VERSION ""

NS_ :

BS_:

BU_: XXX

BO_ 85 CID_OBBIEO: 8 XXX
 SG_ sig_ztylyv : 40|1@1+ (1,0) [0|1] "" XXX
 SG_ sig_mnrkns : 56|8@1+ (1,0) [0|255] "" XXX

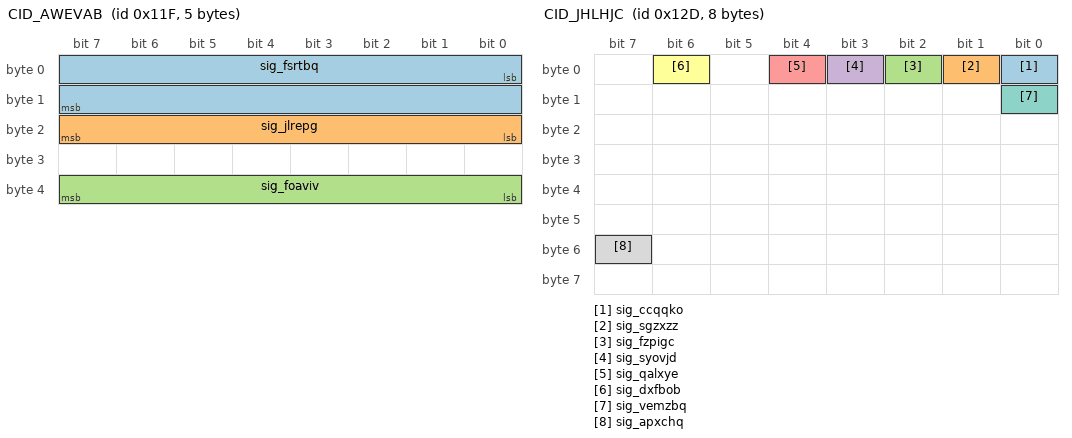
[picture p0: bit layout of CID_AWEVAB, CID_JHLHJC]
BO_ 287 CID_AWEVAB: 5 XXX
 SG_ sig_fsrtbq : 0|16@1- (0.1,0) [-450|450] "" XXX
 SG_ sig_jlrepg : 16|8@1+ (4,0) [0|1020] "" XXX
 SG_ sig_foaviv : 32|8@1+ (1,0) [0|255] "" XXX

BO_ 289 CID_IADQPU: 8 XXX
 SG_ sig_tpgtbw : 0|12@1+ (1,0) [0|255] "" XXX

BO_ 301 CID_JHLHJC: 8 XXX
 SG_ sig_ccqqko : 0|1@0+ (1,0) [0|1] "" XXX
 SG_ sig_sgzxzz : 1|1@0+ (1,0) [0|1] "" XXX
 SG_ sig_fzpigc : 2|1@0+ (1,0) [0|1] "" XXX
 SG_ sig_syovjd : 3|1@0+ (1,0) [0|1] "" XXX
 SG_ sig_qalxye : 4|1@0+ (1,0) [0|1] "" XXX
 SG_ sig_dxfbob : 6|1@0+ (1,0) [0|1] "" XXX
 SG_ sig_vemzbq : 8|1@0+ (1,0) [0|1] "" XXX
 SG_ sig_apxchq : 55|1@0+ (1,0) [0|1] "" XXX

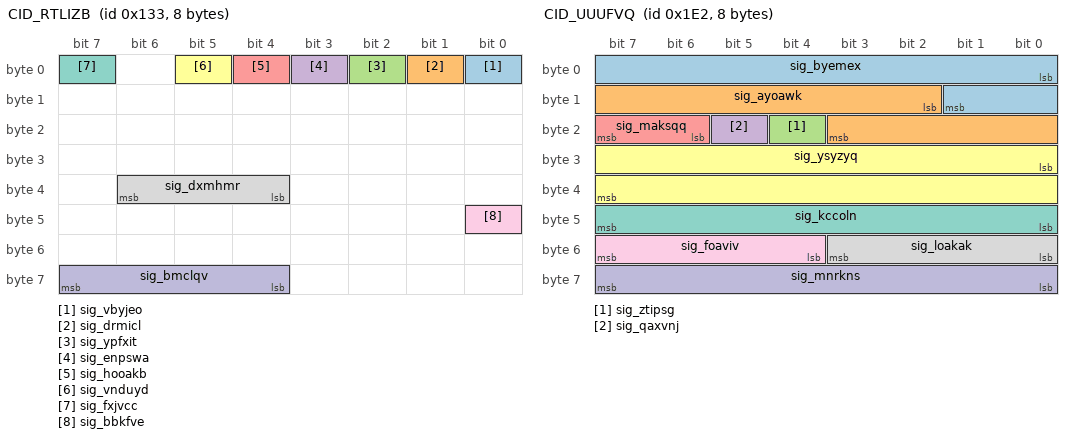
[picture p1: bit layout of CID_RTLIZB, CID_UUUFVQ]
BO_ 307 CID_RTLIZB: 8 XXX
 SG_ sig_vbyjeo : 0|1@0+ (1,0) [0|1] "" XXX
 SG_ sig_drmicl : 1|1@1+ (1,0) [0|1] "" XXX
 SG_ sig_ypfxit : 2|1@1+ (1,0) [0|1] "" XXX
 SG_ sig_enpswa : 3|1@1+ (1,0) [0|1] "" XXX
 SG_ sig_hooakb : 4|1@0+ (1,0) [0|1] "" XXX
 SG_ sig_vnduyd : 5|1@0+ (1,0) [0|1] "" XXX
 SG_ sig_fxjvcc : 7|1@0+ (1,0) [0|1] "" XXX
 SG_ sig_dxmhmr : 36|3@1+ (1,0) [0|7] "" XXX
 SG_ sig_bbkfve : 40|1@0+ (1,0) [0|1] "" XXX
 SG_ sig_bmclqv : 63|4@0+ (1,0) [0|15] "" XXX

BO_ 482 CID_UUUFVQ: 8 XXX
 SG_ sig_byemex : 0|10@1- (0.01,0) [0|5] "" XXX
 SG_ sig_ayoawk : 10|10@1- (0.01,0) [-5|0] "" XXX
 SG_ sig_ztipsg : 20|1@0+ (1,0) [0|1] "" XXX
 SG_ sig_qaxvnj : 21|1@0+ (1,0) [0|1] "" XXX
 SG_ sig_maksqq : 22|2@1+ (1,0) [0|1] "" XXX
 SG_ sig_ysyzyq : 24|16@1- (0.1,0) [-780|779.9] "" XXX
 SG_ sig_kccoln : 47|8@0+ (1,0) [0|255] "" XXX
 SG_ sig_loakak : 48|4@1+ (1,0) [0|15] "" XXX
 SG_ sig_foaviv : 52|4@1+ (1,0) [0|15] "" XXX
 SG_ sig_mnrkns : 56|8@1+ (1,0) [0|255] "" XXX

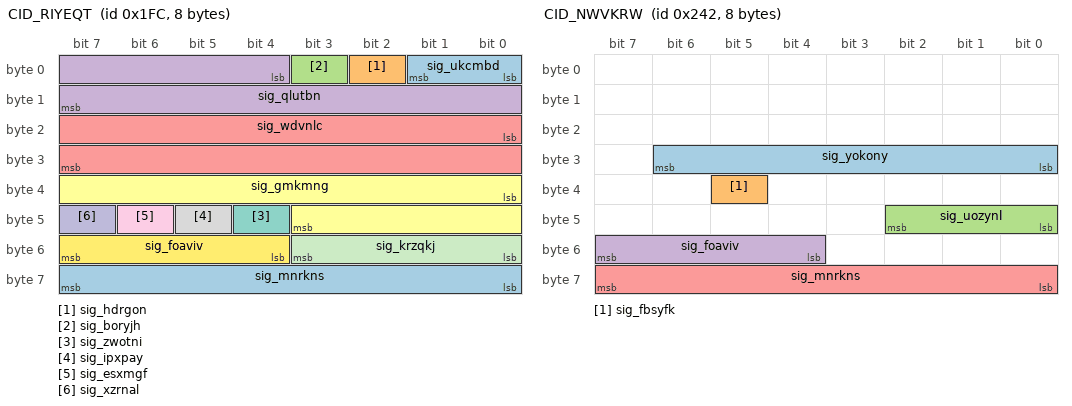
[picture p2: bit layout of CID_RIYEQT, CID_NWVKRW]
BO_ 508 CID_RIYEQT: 8 XXX
 SG_ sig_ukcmbd : 0|2@1+ (1,0) [0|1] "" XXX
 SG_ sig_hdrgon : 2|1@1+ (1,0) [0|1] "" XXX
 SG_ sig_boryjh : 3|1@0+ (1,0) [0|1] "" XXX
 SG_ sig_qlutbn : 4|12@1- (1,0) [-2048|2047] "" XXX
 SG_ sig_wdvnlc : 16|16@1- (0.1,0) [-780|779.9] "Deg" XXX
 SG_ sig_gmkmng : 32|12@1- (0.01,0) [0|63] "" XXX
 SG_ sig_zwotni : 44|1@0+ (1,0) [0|1] "" XXX
 SG_ sig_ipxpay : 45|1@1+ (1,0) [0|255] "" XXX
 SG_ sig_esxmgf : 46|1@1+ (1,0) [0|1] "" XXX
 SG_ sig_xzrnal : 47|1@0+ (1,0) [0|3] "" XXX
 SG_ sig_krzqkj : 48|4@1+ (1,0) [0|15] "" XXX
 SG_ sig_foaviv : 52|4@1+ (1,0) [0|15] "" XXX
 SG_ sig_mnrkns : 56|8@1+ (1,0) [0|255] "" XXX

BO_ 578 CID_NWVKRW: 8 XXX
 SG_ sig_yokony : 30|7@0+ (1,0) [0|127] "" XXX
 SG_ sig_fbsyfk : 37|1@0+ (1,0) [0|1] "" XXX
 SG_ sig_uozynl : 40|3@1+ (1,0) [0|7] "" XXX
 SG_ sig_foaviv : 55|4@0+ (1,0) [0|15] "" XXX
 SG_ sig_mnrkns : 56|8@1+ (1,0) [0|255] "" XXX

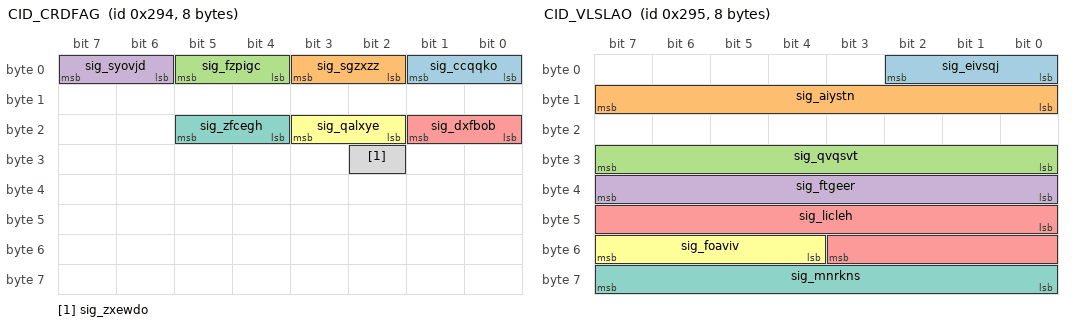
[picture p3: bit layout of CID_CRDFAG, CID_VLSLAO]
BO_ 660 CID_CRDFAG: 8 XXX
 SG_ sig_ccqqko : 1|2@0+ (1,0) [0|3] "" XXX
 SG_ sig_sgzxzz : 3|2@0+ (1,0) [0|3] "" XXX
 SG_ sig_fzpigc : 5|2@0+ (1,0) [0|3] "" XXX
 SG_ sig_syovjd : 7|2@0+ (1,0) [0|3] "" XXX
 SG_ sig_dxfbob : 17|2@0+ (1,0) [0|3] "" XXX
 SG_ sig_qalxye : 19|2@0+ (1,0) [0|3] "" XXX
 SG_ sig_zfcegh : 21|2@0+ (1,0) [0|3] "" XXX
 SG_ sig_zxewdo : 26|1@0+ (1,0) [0|1] "" XXX

BO_ 661 CID_VLSLAO: 8 XXX
 SG_ sig_eivsqj : 2|3@0+ (1,0) [0|7] "" XXX
 SG_ sig_aiystn : 15|8@0+ (1,0) [0|255] "" XXX
 SG_ sig_qvqsvt : 31|8@0+ (1,0) [0|255] "" XXX
 SG_ sig_ftgeer : 32|8@1+ (1,0) [0|255] "" XXX
 SG_ sig_licleh : 40|12@1+ (1,0) [0|255] "" XXX
 SG_ sig_foaviv : 52|4@1+ (1,0) [0|15] "" XXX
 SG_ sig_mnrkns : 63|8@0+ (1,0) [0|255] "" XXX

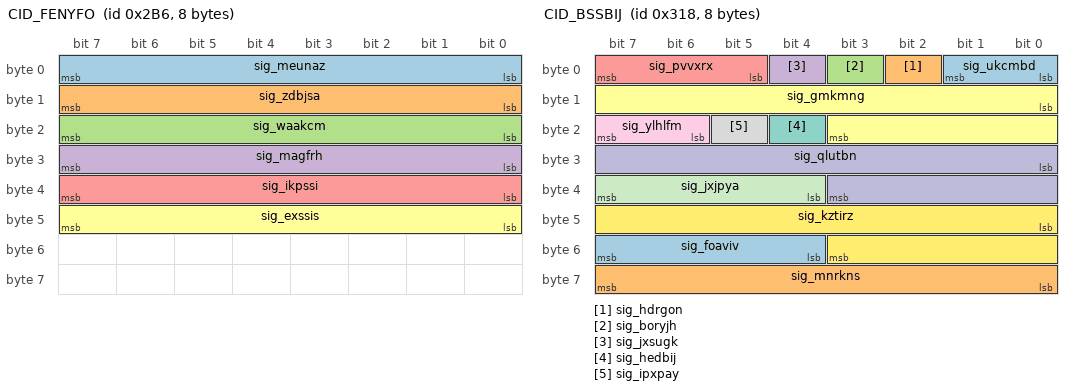
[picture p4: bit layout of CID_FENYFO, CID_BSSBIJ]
BO_ 694 CID_FENYFO: 8 XXX
 SG_ sig_meunaz : 7|8@0+ (1,0) [0|255] "" XXX
 SG_ sig_zdbjsa : 15|8@0+ (1,0) [0|255] "" XXX
 SG_ sig_waakcm : 23|8@0+ (1,0) [0|255] "" XXX
 SG_ sig_magfrh : 31|8@0+ (1,0) [0|255] "" XXX
 SG_ sig_ikpssi : 39|8@0+ (1,0) [0|255] "" XXX
 SG_ sig_exssis : 47|8@0+ (1,0) [0|255] "" XXX

BO_ 790 CID_SJYXFS: 8 XXX
 SG_ sig_xmqwfm : 3|4@0+ (1,0) [0|1] "" XXX
 SG_ sig_wkslko : 4|2@1+ (1,0) [0|3] "" XXX
 SG_ sig_kwgcie : 6|2@1+ (1,0) [0|3] "" XXX
 SG_ sig_zuxlpg : 8|2@1+ (1,0) [0|3] "" XXX
 SG_ sig_cudveg : 10|1@1+ (1,0) [0|1] "" XXX
 SG_ sig_dhqlja : 11|4@1+ (1,0) [0|1] "" XXX
 SG_ sig_aytxbb : 15|1@0+ (1,0) [0|1] "" XXX
 SG_ sig_ysyzyq : 16|11@1- (1,0) [-1024|1023] "" XXX
 SG_ sig_ztipsg : 27|1@1+ (1,0) [0|1] "" XXX
 SG_ sig_qaxvnj : 28|1@1+ (1,0) [0|3] "" XXX
 SG_ sig_kjrufc : 29|1@0+ (1,0) [0|1] "" XXX
 SG_ sig_eovbcm : 30|1@0+ (1,0) [0|1] "" XXX
 SG_ sig_phblbt : 31|1@0+ (1,0) [0|1] "" XXX
 SG_ sig_gevymy : 32|2@1+ (1,0) [0|3] "" XXX
 SG_ sig_ntkcop : 34|2@1+ (1,0) [0|3] "" XXX
 SG_ sig_kwwqzx : 36|4@1+ (1,0) [0|3] "" XXX
 SG_ sig_ixvluv : 40|8@1+ (5,-5) [-5|1270] "" XXX
 SG_ sig_lbctgd : 49|2@0+ (1,0) [0|3] "" XXX
 SG_ sig_plknqa : 51|2@0+ (1,0) [0|3] "" XXX
 SG_ sig_foaviv : 52|4@1+ (1,0) [0|15] "" XXX
 SG_ sig_mnrkns : 56|8@1+ (1,0) [0|15] "" XXX

BO_ 792 CID_BSSBIJ: 8 XXX
 SG_ sig_ukcmbd : 0|2@1+ (1,0) [0|1] "" XXX
 SG_ sig_hdrgon : 2|1@1+ (1,0) [0|1] "" XXX
 SG_ sig_boryjh : 3|1@1+ (1,0) [0|1] "" XXX
 SG_ sig_jxsugk : 4|1@1+ (1,0) [0|1] "" XXX
 SG_ sig_pvvxrx : 5|3@1+ (1,0) [0|1] "" XXX
 SG_ sig_gmkmng : 8|12@1- (1,0) [-2048|2047] "" XXX
 SG_ sig_hedbij : 20|1@1+ (1,0) [0|1] "" XXX
 SG_ sig_ipxpay : 21|1@1+ (1,0) [0|1] "" XXX
 SG_ sig_ylhlfm : 22|2@1+ (1,0) [0|15] "" XXX
 SG_ sig_qlutbn : 24|12@1- (1,0) [-2048|2047] "" XXX
 SG_ sig_jxjpya : 36|4@1+ (1,0) [0|15] "" XXX
 SG_ sig_kztirz : 40|12@1+ (1,0) [0|4095] "" XXX
 SG_ sig_foaviv : 52|4@1+ (1,0) [0|15] "" XXX
 SG_ sig_mnrkns : 56|8@1+ (1,0) [0|255] "" XXX

BO_ 813 CID_CFWAIZ: 8 XXX
 SG_ sig_rirhkn : 0|9@1+ (0.5,0) [0|255.5] "" XXX
 SG_ sig_psxjfy : 9|1@1+ (1,0) [0|1] "" XXX
 SG_ sig_mevbcs : 10|3@1+ (1,0) [0|7] "" XXX
 SG_ sig_zgzzio : 13|3@1+ (1,0) [0|7] "" XXX
 SG_ sig_kjnywh : 16|1@1+ (1,0) [0|1] "" XXX
 SG_ sig_ogmbuf : 17|1@1+ (1,0) [0|1] "" XXX
 SG_ sig_boryjh : 18|1@1+ (1,0) [0|1] "" XXX
 SG_ sig_sevmrq : 19|3@1+ (1,0) [0|1] "" XXX
 SG_ sig_htkqln : 22|1@0+ (1,0) [0|1] "" XXX
 SG_ sig_kjbxla : 23|1@0+ (1,0) [0|1] "" XXX
 SG_ sig_zuxlpg : 24|1@1+ (1,0) [0|1] "" XXX
 SG_ sig_jyohfm : 25|7@1+ (1,0) [0|127] "" XXX
 SG_ sig_zygpcq : 32|4@1+ (1,0) [0|15] "" XXX
 SG_ sig_tngaaq : 36|12@1+ (1,0) [0|4095] "" XXX
 SG_ sig_foaviv : 48|4@1+ (1,0) [0|15] "" XXX
 SG_ sig_jwvlrv : 55|4@0+ (1,0) [0|15] "" XXX
 SG_ sig_mnrkns : 56|8@1+ (1,0) [0|255] "" XXX

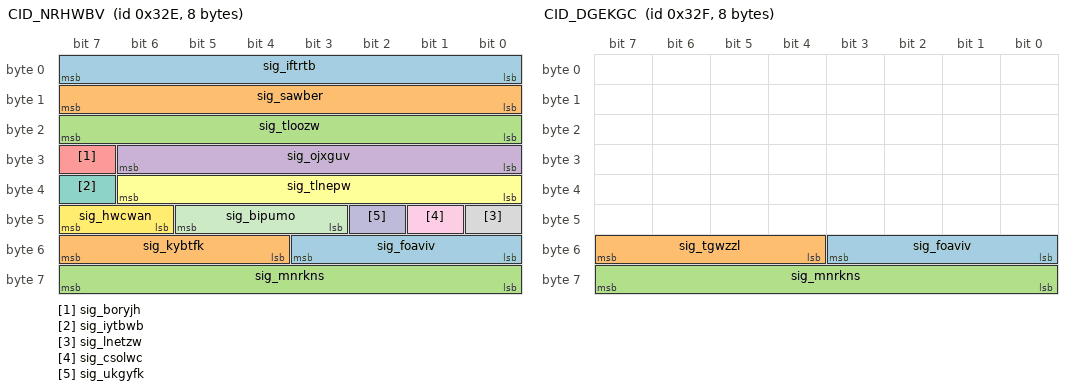
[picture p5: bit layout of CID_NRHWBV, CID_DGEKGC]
BO_ 814 CID_NRHWBV: 8 XXX
 SG_ sig_iftrtb : 0|8@1+ (0.05,-5) [-100|155] "" XXX
 SG_ sig_sawber : 8|8@1+ (0.05,-5) [0|1.26] "" XXX
 SG_ sig_tloozw : 16|8@1+ (0.05,-5) [0|1.26] "" XXX
 SG_ sig_ojxguv : 24|7@1+ (0.2,0) [0|12.7] "" XXX
 SG_ sig_boryjh : 31|1@0+ (1,0) [0|1] "" XXX
 SG_ sig_tlnepw : 32|7@1+ (0.2,-16) [0|12.7] "" XXX
 SG_ sig_iytbwb : 39|1@0+ (1,0) [0|1] "" XXX
 SG_ sig_lnetzw : 40|1@0+ (1,0) [0|1] "" XXX
 SG_ sig_csolwc : 41|1@0+ (1,0) [0|1] "" XXX
 SG_ sig_ukgyfk : 42|1@1+ (1,0) [0|3] "" XXX
 SG_ sig_bipumo : 45|3@0+ (1,0) [0|1] "" XXX
 SG_ sig_hwcwan : 46|2@1+ (1,0) [0|3] "" XXX
 SG_ sig_foaviv : 48|4@1+ (1,0) [0|15] "" XXX
 SG_ sig_kybtfk : 55|4@0+ (1,0) [0|15] "" XXX
 SG_ sig_mnrkns : 56|8@1+ (1,0) [0|255] "" XXX

BO_ 815 CID_DGEKGC: 8 XXX
 SG_ sig_foaviv : 48|4@1+ (1,0) [0|15] "" XXX
 SG_ sig_tgwzzl : 55|4@0+ (1,0) [0|15] "" XXX
 SG_ sig_mnrkns : 56|8@1+ (1,0) [0|255] "" XXX

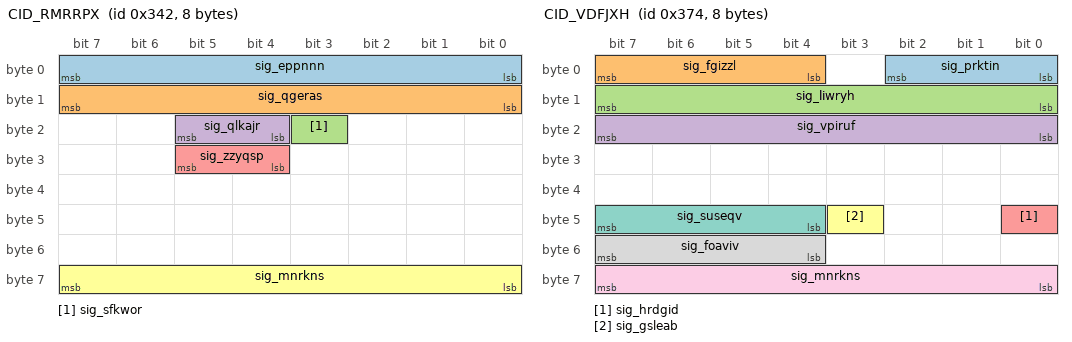
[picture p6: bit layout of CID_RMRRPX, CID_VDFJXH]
BO_ 834 CID_RMRRPX: 8 XXX
 SG_ sig_eppnnn : 0|8@1+ (0.01,0) [0|2.55] "" XXX
 SG_ sig_qgeras : 8|8@1+ (0.01,0) [0|2.55] "" XXX
 SG_ sig_sfkwor : 19|1@1+ (1,0) [0|1] "" XXX
 SG_ sig_qlkajr : 20|2@1+ (1,0) [0|255] "" XXX
 SG_ sig_zzyqsp : 28|2@1+ (1,0) [0|1] "" XXX
 SG_ sig_mnrkns : 56|8@1+ (1,0) [0|255] "" XXX

 BO_ 884 CID_VDFJXH: 8 MRR
 SG_ sig_prktin : 2|3@0+ (1,0) [0|3] "" MRR
 SG_ sig_fgizzl : 7|4@0+ (1,0) [0|15] "" MRR
 SG_ sig_liwryh : 15|8@0+ (0.1,-12) [0|255] "" MRR
 SG_ sig_vpiruf : 23|8@0+ (1,-100) [0|255] "" MRR
 SG_ sig_hrdgid : 40|1@0+ (1,0) [0|3] "" MRR
 SG_ sig_gsleab : 43|1@0+ (1,0) [0|1] "" XXX
 SG_ sig_suseqv : 44|4@1+ (1,0) [0|15] "" XXX
 SG_ sig_foaviv : 52|4@1+ (1,0) [0|15] "" MRR
 SG_ sig_mnrkns : 56|8@1+ (1,0) [0|255] "" MRR

BO_ 944 CID_CCQNZS: 8 XXX
 SG_ sig_gbwmyi : 1|2@0+ (1,0) [0|3] "" XXX
 SG_ sig_kfeqgy : 2|1@0+ (1,0) [0|1] "" XXX
 SG_ sig_yizijv : 4|2@0+ (1,0) [0|3] "" XXX
 SG_ sig_grtwax : 5|1@0+ (1,0) [0|1] "" XXX
 SG_ sig_zdtpzc : 6|1@0+ (1,0) [0|1] "" XXX
 SG_ sig_yrlzhn : 7|1@0+ (1,0) [0|1] "" XXX
 SG_ sig_ockgql : 8|1@0+ (1,0) [0|1] "" XXX
 SG_ sig_oqilhc : 11|3@0+ (1,0) [0|7] "" XXX
 SG_ sig_eaewjl : 12|1@0+ (1,0) [0|1] "" XXX
 SG_ sig_vezjom : 14|2@0+ (1,0) [0|3] "" XXX
 SG_ sig_oqmuey : 15|1@0+ (1,0) [0|1] "" XXX
 SG_ sig_bfrefm : 16|1@0+ (1,0) [0|1] "" XXX
 SG_ sig_omoltc : 18|2@0+ (1,0) [0|3] "" XXX
 SG_ sig_gkjpfo : 19|1@0+ (1,0) [0|1] "" XXX
 SG_ sig_jcglqv : 23|4@0+ (1,0) [0|15] "" XXX
 SG_ sig_weolzz : 24|28@1+ (1,0) [0|268435455] "" XXX
 SG_ sig_foaviv : 52|4@1+ (1,0) [0|15] "" XXX
 SG_ sig_mnrkns : 56|8@1+ (1,0) [0|255] "" XXX

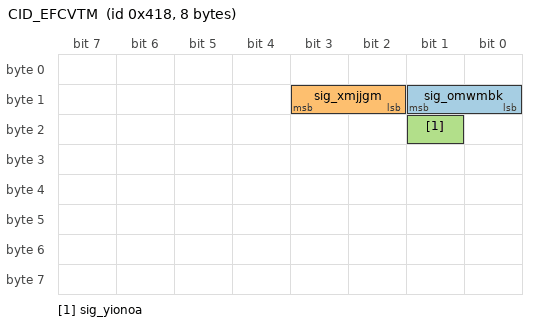
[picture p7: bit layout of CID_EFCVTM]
BO_ 1048 CID_EFCVTM: 8 XXX
 SG_ sig_omwmbk : 9|2@0+ (1,0) [0|1] "" XXX
 SG_ sig_xmjjgm : 11|2@0+ (1,0) [0|1] "" XXX
 SG_ sig_yionoa : 17|1@0+ (1,0) [0|1] "" XXX

VAL_ 578 sig_uozynl 4 "D" 2 "R" 3 "N" 1 "P";
VAL_ 790 sig_xmqwfm 11 "AutoFullBeamActive" 2 "AutoFullBeamInactive";
VAL_ 790 sig_wkslko 0 "GRAY" 1 "GREEN" 2 "YELLOW" 3 "RED";
VAL_ 790 sig_kwgcie 3 "ALARM_AND_LKA" 2 "LKA" 1 "ALARM" 0 "DISABLE";
VAL_ 790 sig_ntkcop 0 "GRAY" 1 "GREEN" 2 "YELLOW" 3 "RED";
VAL_ 790 sig_lbctgd 0 "VIBRATION" 1 "AUDIO" 2 "AUDIO_AND_VIBRATION";
VAL_ 792 sig_ukcmbd 0 "NotReady" 1 "Ready" 2 "Active" 3 "TemporaryFail";
VAL_ 813 sig_mevbcs 4 "4BAR" 3 "3BAR" 2 "2BAR" 1 "1BAR";
VAL_ 813 sig_sevmrq 0 "OFF" 2 "ACC_ON" 3 "ACC_ACTIVE" 5 "FORCE_ACCEL" 7 "ERROR";
VAL_ 813 sig_jyohfm 36 "ACC_ERROR" 22 "OVERRIDE" 12 "ENGAGE" 8 "DISENGAGE" 20 "ACC_ON" 32 "ACC_OFF" 48 "CHECK_GEAR_D" 16 "FORCE_ACCEL" 0 "NONE";
VAL_ 814 sig_bipumo 0 "Off" 1 "Passive" 2 "StandBy" 3 "ActiveControl" 4 "BrakeOnly" 5 "Override" 6 "Standstill" 7 "Failure";
VAL_ 814 sig_hwcwan 0 "Softoff" 1 "Fastoff" 2 "Immediateoff" 3 "Initial";
VAL_ 834 sig_qlkajr 2 "SPORT" 1 "ECO" 0 "SNOW";
VAL_ 834 sig_zzyqsp 3 "HEV" 2 "FORCE_EV" 1 "EV";
VAL_ 944 sig_yizijv 0 "NOTPRESSED" 1 "DOWN_SETSPEED" 3 "UP_RESETSPEED";
